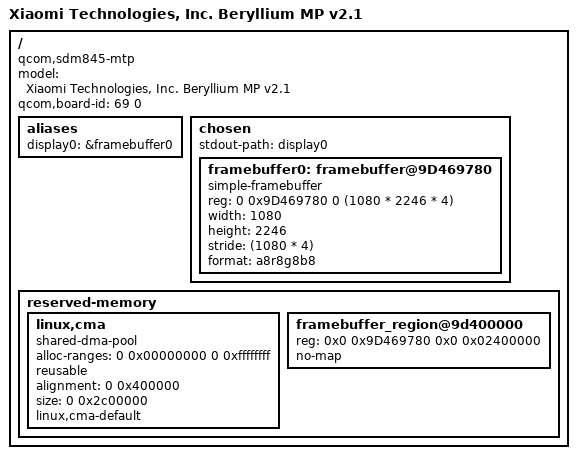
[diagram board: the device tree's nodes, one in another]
/* Copyright (c) 2017, The Linux Foundation. All rights reserved.
 * Copyright (C) 2018 XiaoMi, Inc.
 *
 * This program is free software; you can redistribute it and/or modify
 * it under the terms of the GNU General Public License version 2 and
 * only version 2 as published by the Free Software Foundation.
 *
 * This program is distributed in the hope that it will be useful,
 * but WITHOUT ANY WARRANTY; without even the implied warranty of
 * MERCHANTABILITY or FITNESS FOR A PARTICULAR PURPOSE.  See the
 * GNU General Public License for more details.
 */


/dts-v1/;

#include "sdm845-v2.1.dtsi"
#include "sdm845-sde-display.dtsi"
#include "beryllium-mp-pinctrl.dtsi"
#include "beryllium-mp.dtsi"
#include "beryllium-audio-overlay.dtsi"

/ {
	model = "Xiaomi Technologies, Inc. Beryllium MP v2.1";
	compatible = "qcom,sdm845-mtp", "qcom,sdm845", "qcom,mtp";
	qcom,board-id = <69 0>;
	
	aliases {
		display0 = &framebuffer0;
	};

	chosen {
		#address-cells = <2>;
		#size-cells = <2>;
		ranges;

		// For simplefb hack
		stdout-path = "display0";

		/*
		 * hack: Use framebuffer setup by the bootloader for simplefb.
		 * the address is taken from the bootloader config (strings xbl.img | grep "Display Reserved")
		 */
		framebuffer0: framebuffer@9D469780 {
			compatible = "simple-framebuffer";
			reg = <0 0x9D469780 0 (1080 * 2246 * 4)>;
			width = <1080>;
			height = <2246>;
			stride = <(1080 * 4)>;
			format = "a8r8g8b8";
		};
	};

	reserved-memory {
		#address-cells = <2>;
		#size-cells = <2>;
		ranges;

		linux,cma {
			compatible = "shared-dma-pool";
			alloc-ranges = <0 0x00000000 0 0xffffffff>;
			reusable;
			alignment = <0 0x400000>;
			size = <0 0x2c00000>;
			linux,cma-default;
		};

		framebuffer_region@9d400000 {
			reg = <0x0 0x9D469780 0x0 0x02400000>;
			no-map;

		};
	};
};


